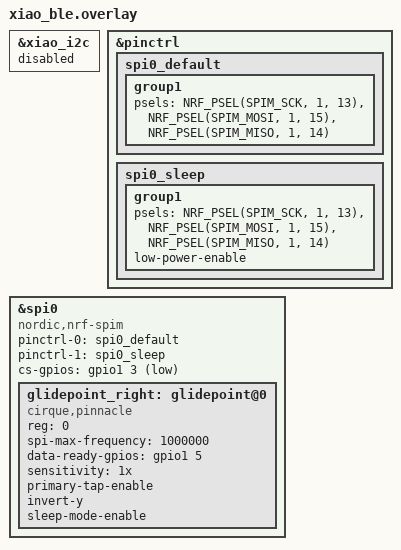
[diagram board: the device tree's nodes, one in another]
/**
 * Generated by Shield Wizard for ZMK
 * Applies to shield "melior_peripheral_right" with board "xiao_ble" only
 */

&xiao_i2c {
    status = "disabled";
};

// pin control for spi0
// - SCK on GPIO 1.13
// - MOSI on GPIO 1.15
// - MISO on GPIO 1.14
&pinctrl {
    /* configuration for spi0 device, default state */
    spi0_default: spi0_default {
        group1 {
            psels = <NRF_PSEL(SPIM_SCK, 1, 13)>,
                <NRF_PSEL(SPIM_MOSI, 1, 15)>,
                <NRF_PSEL(SPIM_MISO, 1, 14)>;
        };
    };

     spi0_sleep: spi0_sleep {
        group1 {
            psels = <NRF_PSEL(SPIM_SCK, 1, 13)>,
                    <NRF_PSEL(SPIM_MOSI, 1, 15)>,
                    <NRF_PSEL(SPIM_MISO, 1, 14)>;
            low-power-enable;
        };
    };

};
&spi0 {
   compatible = "nordic,nrf-spim";
   status = "okay";
   pinctrl-0 = <&spi0_default>;
   pinctrl-1 = <&spi0_sleep>;
   pinctrl-names = "default", "sleep";
};

// devices on spi0

// CS pins for devices on spi0
&spi0 {
   cs-gpios = <&gpio1 3 GPIO_ACTIVE_LOW>;
};

&spi0 {
   glidepoint_right:  glidepoint@0 {
        compatible = "cirque,pinnacle";
        reg = <0>;
        spi-max-frequency = <1000000>;
        status = "okay";
        data-ready-gpios = <&gpio1 5 (GPIO_ACTIVE_HIGH)>;
        sensitivity = "1x";
        primary-tap-enable;
        invert-y;
        sleep-mode-enable;
    };
};

